# HDSC_HC32L110 register map
Vendor: HDSC Co.Ltd; Series: ARMCM0P; File version: 1.2
CPU: CM0 r0p0, little endian, no MPU, no FPU, 3 interrupt priority bits
Registers are 32-bit, read-write, reset 0x0 unless marked. A register's access mark holds for its fields unless they carry their own. Offsets are from the block's base; lines under a group give offsets from that group; [hi:lo] are bit positions; {n}, {i} and the like mark numbered series; 'fields as' and 'values as' point back to an identical list; <NAME> marks a mode.

## Memory map
0x40000000 UART0 size 0x15 — desc UART
0x40000100 UART1 size 0x15 — desc UART
0x40000200 LPUART size 0x15
0x40000400 I2C size 0x18
0x40000800 SPI size 0x10
0x40000C00 BT0 size 0x18 — desc BT
0x40000C00 LPTIMER size 0x78
0x40000C00 WDT size 0x86
0x40000C20 BT1 size 0x18 — desc BT
0x40000C40 BT2 size 0x18 — desc BT
0x40001000 PCA size 0x64
0x40001400 RTC size 0x32
0x40001800 CLK_TRIM size 0x1C
0x40002000 CLOCK size 0x54
0x4000201C RESET size 0xF
0x40002400 ADC size 0x74
0x40002400 BGR size 0x7C
0x40002400 LVD size 0x30
0x40002400 VC size 0x28
0x40003000 ADT0 size 0x400 — desc ADT
0x40003400 ADT1 size 0x400 — desc ADT
0x40003800 ADT2 size 0x400 — desc ADT
0x40020000 FLASH size 0x34
0x40020400 RAM size 0x10
0x40020900 CRC size 0x100
0x40020C00 GPIO size 0x400

## ADC
Base 0x40002400
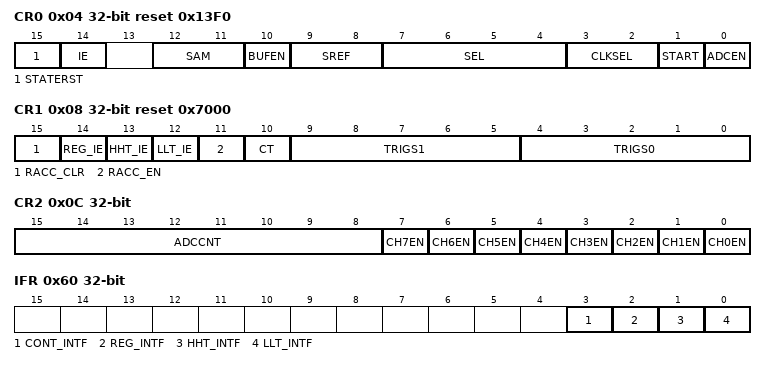
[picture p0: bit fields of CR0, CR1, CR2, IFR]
0x04 CR0 reset 0x13F0 (reset mask 0x5FFF)
  [15] STATERST, [14] IE, [12:11] SAM, [10] BUFEN, [9:8] SREF, [7:4] SEL, [3:2] CLKSEL, [1] START, [0] ADCEN
0x08 CR1 reset 0x7000
  [15] RACC_CLR, [14] REG_IE, [13] HHT_IE, [12] LLT_IE, [11] RACC_EN, [10] CT, [9:5] TRIGS1, [4:0] TRIGS0
0x0C CR2
  [15:8] ADCCNT, [n] CH{n}EN (n=0..7)
{0x30+4i} RESULT{i} ro (i=0..8)
  [11:0] RESULT{i}
0x54 RESULT_ACC ro
  [19:0] RESULT_ACC
0x58 HT ro reset 0xFFF
  [11:0] RESULT_HIGH
0x5C LT ro
  [11:0] RESULT_LOW
0x60 IFR ro
  [3] CONT_INTF, [2] REG_INTF, [1] HHT_INTF, [0] LLT_INTF
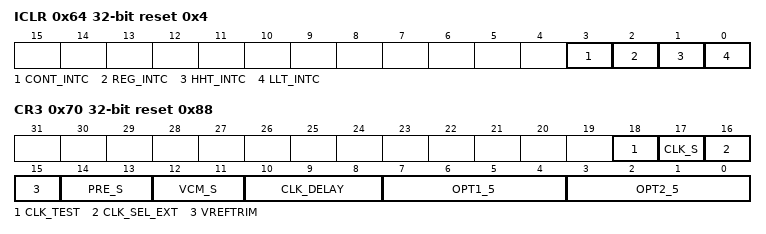
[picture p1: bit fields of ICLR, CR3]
0x64 ICLR wo reset 0x4
  [3] CONT_INTC, [2] REG_INTC, [1] HHT_INTC, [0] LLT_INTC
0x68 RESULT ro
  [11:0] RESULT
0x70 CR3 reset 0x88
  [18] CLK_TEST, [17] CLK_S, [16] CLK_SEL_EXT, [15] VREFTRIM, [14:13] PRE_S, [12:11] VCM_S, [10:8] CLK_DELAY, [7:4] OPT1_5, [3:0] OPT2_5

## ADT0 — desc ADT
Base 0x40003000
Same registers: ADT1 0x40003400, ADT2 0x40003800
0x00 CNTER
  [15:0] CNT
0x04 PERAR reset 0xFFFF
  [15:0] PERA
0x08 PERBR reset 0xFFFF
  [15:0] PERB
0x10 GCMAR reset 0xFFFF
  [15:0] GCMA_D
0x14 GCMBR reset 0xFFFF
  [15:0] GCMB_D
0x18 GCMCR reset 0xFFFF
  [15:0] GCMC_D
0x1C GCMDR reset 0xFFFF
  [15:0] GCMD_D
0x40 DTUAR reset 0xFFFF
  [15:0] DTUA
0x44 DTDAR reset 0xFFFF
  [15:0] DTDA
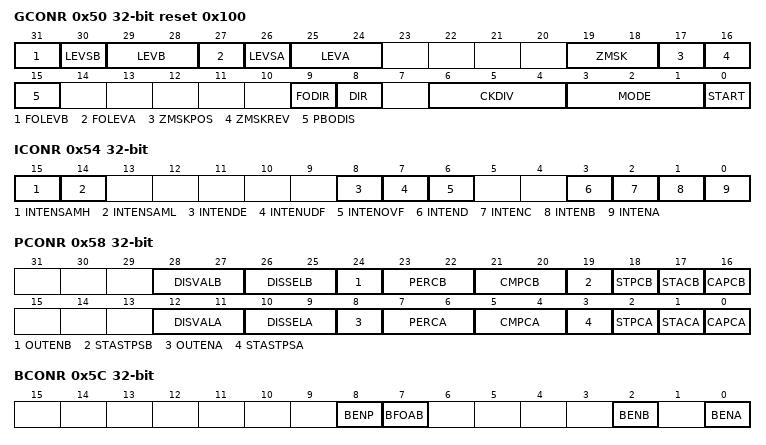
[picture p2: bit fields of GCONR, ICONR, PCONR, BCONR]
0x50 GCONR reset 0x100
  [31] FOLEVB, [30] LEVSB, [29:28] LEVB, [27] FOLEVA, [26] LEVSA, [25:24] LEVA, [19:18] ZMSK, [17] ZMSKPOS, [16] ZMSKREV, [15] PBODIS, [9] FODIR, [8] DIR, [6:4] CKDIV, [3:1] MODE, [0] START
0x54 ICONR
  [15] INTENSAMH, [14] INTENSAML, [8] INTENDE, [7] INTENUDF, [6] INTENOVF, [3] INTEND, [2] INTENC, [1] INTENB, [0] INTENA
0x58 PCONR
  [28:27] DISVALB, [26:25] DISSELB, [24] OUTENB, [23:22] PERCB, [21:20] CMPCB, [19] STASTPSB, [18] STPCB, [17] STACB, [16] CAPCB, [12:11] DISVALA, [10:9] DISSELA, [8] OUTENA, [7:6] PERCA, [5:4] CMPCA, [3] STASTPSA, [2] STPCA, [1] STACA, [0] CAPCA
0x5C BCONR
  [8] BENP, [7] BFOAB, [2] BENB, [0] BENA
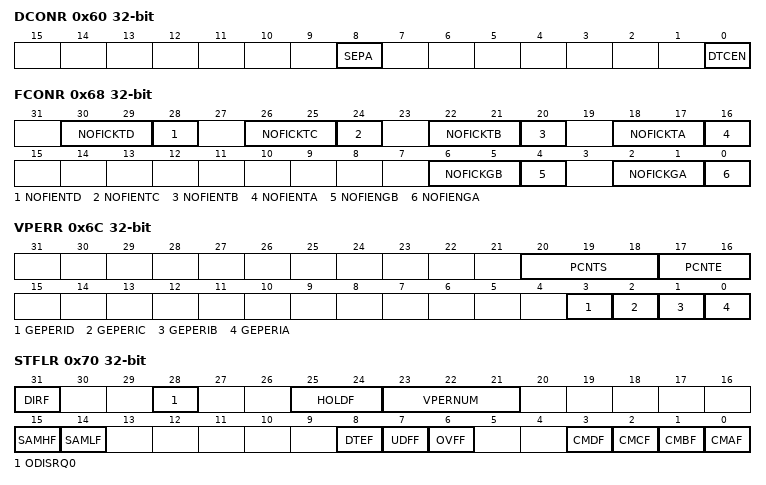
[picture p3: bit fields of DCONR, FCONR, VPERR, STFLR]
0x60 DCONR
  [8] SEPA, [0] DTCEN
0x68 FCONR
  [30:29] NOFICKTD, [28] NOFIENTD, [26:25] NOFICKTC, [24] NOFIENTC, [22:21] NOFICKTB, [20] NOFIENTB, [18:17] NOFICKTA, [16] NOFIENTA, [6:5] NOFICKGB, [4] NOFIENGB, [2:1] NOFICKGA, [0] NOFIENGA
0x6C VPERR
  [20:18] PCNTS, [17:16] PCNTE, [3] GEPERID, [2] GEPERIC, [1] GEPERIB, [0] GEPERIA
0x70 STFLR (reset mask 0x97C0C1CF)
  [31] DIRF ro, [28] ODISRQ0 ro, [25:24] HOLDF ro, [23:21] VPERNUM ro, [15] SAMHF ro, [14] SAMLF ro, [8] DTEF, [7] UDFF, [6] OVFF, [3] CMDF, [2] CMCF, [1] CMBF, [0] CMAF
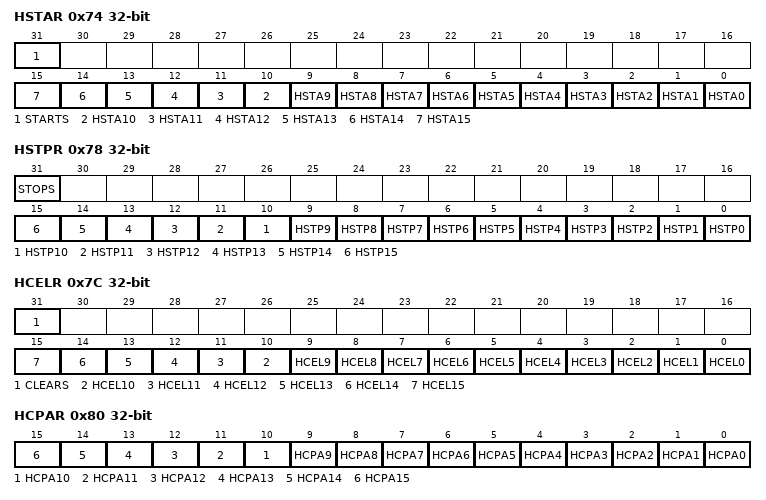
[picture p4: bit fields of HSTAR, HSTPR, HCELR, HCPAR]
0x74 HSTAR
  [31] STARTS, [n] HSTA{n} (n=0..15)
0x78 HSTPR
  [31] STOPS, [n] HSTP{n} (n=0..15)
0x7C HCELR
  [31] CLEARS, [n] HCEL{n} (n=0..15)
0x80 HCPAR
  [n] HCPA{n} (n=0..15)
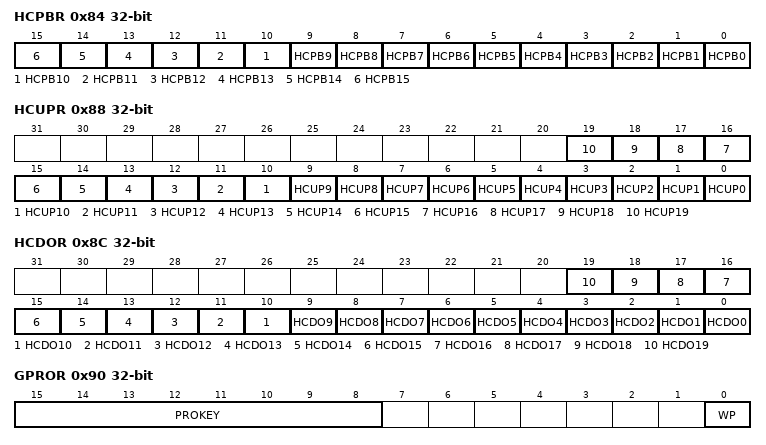
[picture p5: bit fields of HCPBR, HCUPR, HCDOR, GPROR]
0x84 HCPBR
  [n] HCPB{n} (n=0..15)
0x88 HCUPR
  [n] HCUP{n} (n=0..19)
0x8C HCDOR
  [n] HCDO{n} (n=0..19)
0x90 GPROR
  [15:8] PROKEY, [0] WP
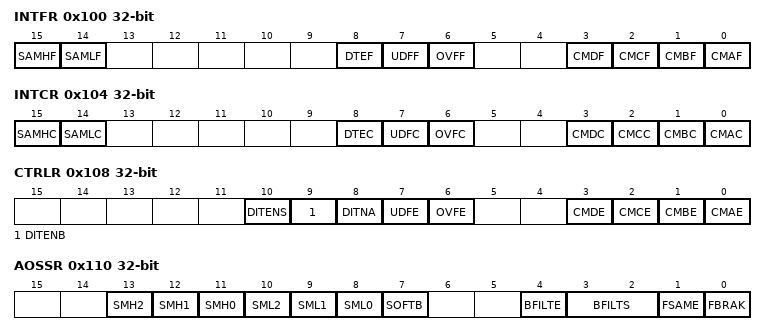
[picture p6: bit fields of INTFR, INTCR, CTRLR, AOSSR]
0x100 INTFR ro
  [15] SAMHF, [14] SAMLF, [8] DTEF, [7] UDFF, [6] OVFF, [3] CMDF, [2] CMCF, [1] CMBF, [0] CMAF
0x104 INTCR wo
  [15] SAMHC, [14] SAMLC, [8] DTEC, [7] UDFC, [6] OVFC, [3] CMDC, [2] CMCC, [1] CMBC, [0] CMAC
0x108 CTRLR
  [10] DITENS, [9] DITENB, [8] DITNA, [7] UDFE, [6] OVFE, [3] CMDE, [2] CMCE, [1] CMBE, [0] CMAE
0x110 AOSSR
  [13] SMH2, [12] SMH1, [11] SMH0, [10] SML2, [9] SML1, [8] SML0, [7] SOFTB, [4] BFILTE, [3:2] BFILTS, [1] FSAME, [0] FBRAK
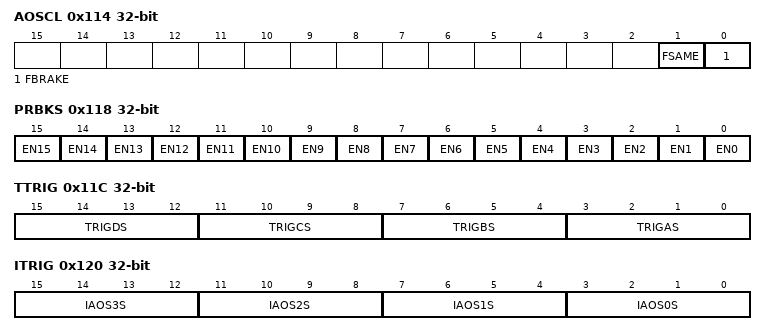
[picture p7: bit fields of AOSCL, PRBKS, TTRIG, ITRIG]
0x114 AOSCL ro
  [1] FSAME, [0] FBRAKE
0x118 PRBKS
  [n] EN{n} (n=0..15)
0x11C TTRIG
  [15:12] TRIGDS, [11:8] TRIGCS, [7:4] TRIGBS, [3:0] TRIGAS
0x120 ITRIG
  [4n+3:4n] IAOS{n}S (n=0..3)
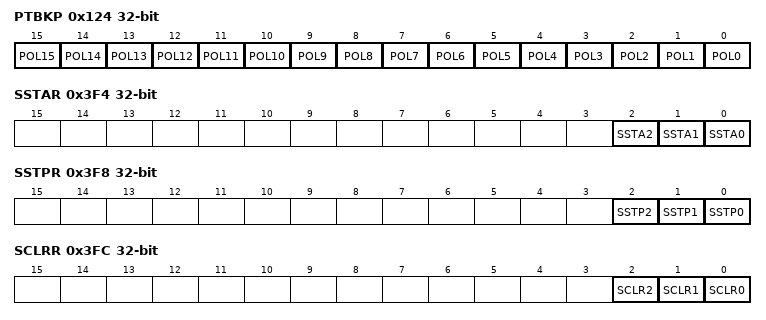
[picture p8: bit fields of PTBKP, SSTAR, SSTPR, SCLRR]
0x124 PTBKP
  [n] POL{n} (n=0..15)
0x3F4 SSTAR
  [2] SSTA2, [1] SSTA1, [0] SSTA0
0x3F8 SSTPR
  [2] SSTP2, [1] SSTP1, [0] SSTP0
0x3FC SCLRR
  [2] SCLR2, [1] SCLR1, [0] SCLR0
